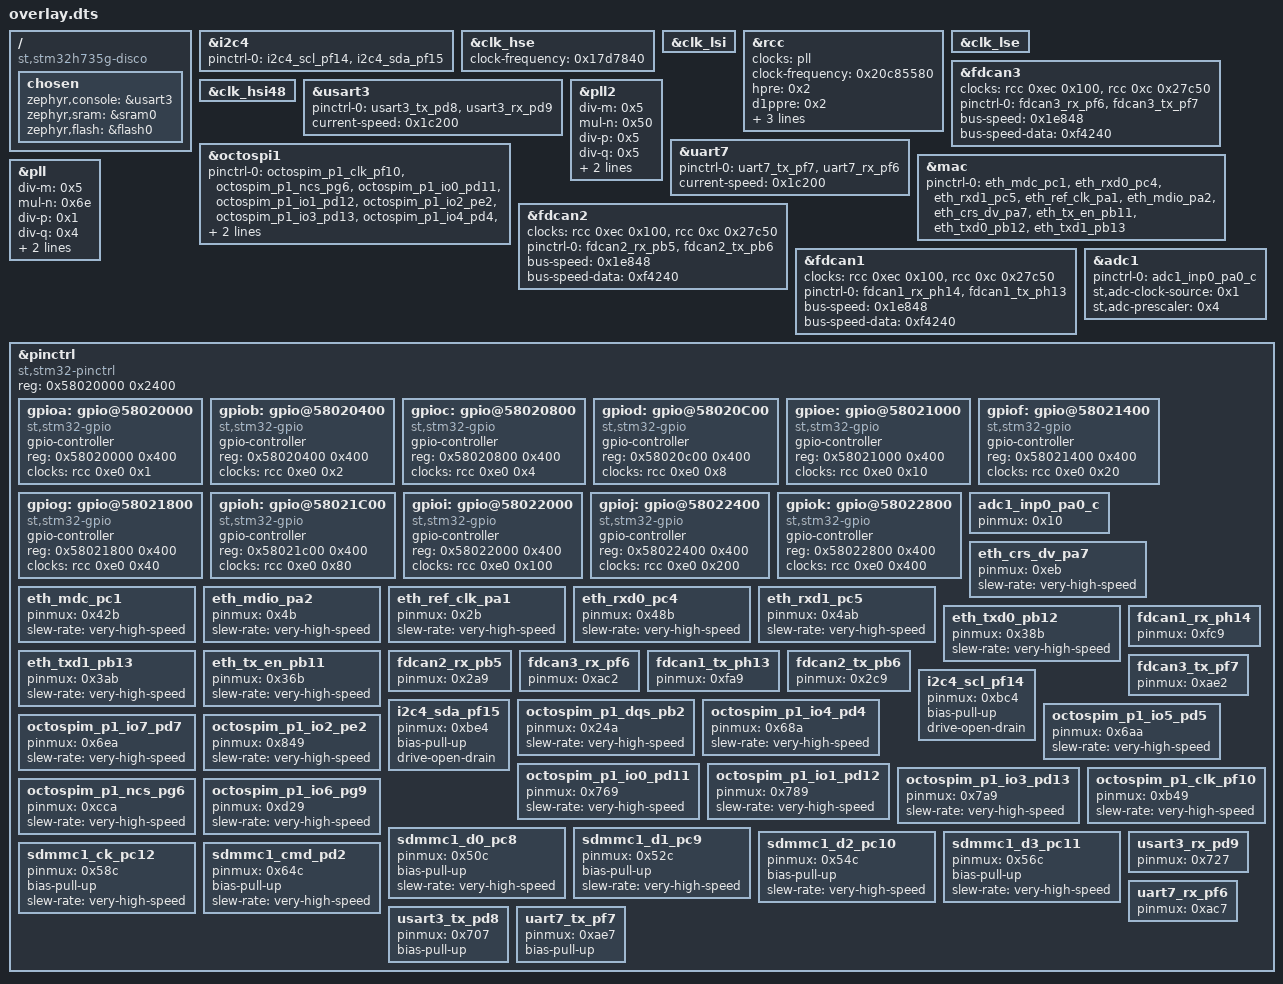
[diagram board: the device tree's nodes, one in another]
/ {
	compatible = "st,stm32h735g-disco";
	chosen {
		zephyr,console = &usart3;
		zephyr,sram = &sram0;
		zephyr,flash = &flash0;
	};
};
&i2c4{
	pinctrl-0 = < &i2c4_scl_pf14 &i2c4_sda_pf15 >;
	pinctrl-names = "default";
};
&clk_hse{
	status = "okay";
	clock-frequency = < 0x17d7840 >;
};
&clk_lsi{
	status = "okay";
};
&rcc{
	clocks = < &pll >;
	clock-frequency = < 0x20c85580 >;
	hpre = < 0x2 >;
	d1ppre = < 0x2 >;
	d2ppre1 = < 0x2 >;
	d2ppre2 = < 0x2 >;
	d3ppre = < 0x2 >;
};
&clk_lse{
	status = "okay";
};
&fdcan3{
	clocks = < &rcc 0xec 0x100 >, < &rcc 0xc 0x27c50 >;
	pinctrl-0 = < &fdcan3_rx_pf6 &fdcan3_tx_pf7 >;
	pinctrl-names = "default";
	bus-speed = < 0x1e848 >;
	bus-speed-data = < 0xf4240 >;
};
&clk_hsi48{
	status = "okay";
};
&usart3{
	status = "okay";
	pinctrl-0 = < &usart3_tx_pd8 &usart3_rx_pd9 >;
	pinctrl-names = "default";
	current-speed = < 0x1c200 >;
};
&pll2{
	status = "okay";
	div-m = < 0x5 >;
	mul-n = < 0x50 >;
	div-p = < 0x5 >;
	div-q = < 0x5 >;
	div-r = < 0x5 >;
	clocks = < &clk_hse >;
};
&octospi1{
	status = "okay";
	pinctrl-0 = < &octospim_p1_clk_pf10 &octospim_p1_ncs_pg6 &octospim_p1_io0_pd11 &octospim_p1_io1_pd12 &octospim_p1_io2_pe2 &octospim_p1_io3_pd13 &octospim_p1_io4_pd4 &octospim_p1_io5_pd5 &octospim_p1_io6_pg9 &octospim_p1_io7_pd7 &octospim_p1_dqs_pb2 >;
	pinctrl-names = "default";
};
&uart7{
	pinctrl-0 = < &uart7_tx_pf7 &uart7_rx_pf6 >;
	pinctrl-names = "default";
	current-speed = < 0x1c200 >;
};
&mac{
	status = "okay";
	pinctrl-0 = < &eth_mdc_pc1 &eth_rxd0_pc4 &eth_rxd1_pc5 &eth_ref_clk_pa1 &eth_mdio_pa2 &eth_crs_dv_pa7 &eth_tx_en_pb11 &eth_txd0_pb12 &eth_txd1_pb13 >;
	pinctrl-names = "default";
};
&fdcan2{
	clocks = < &rcc 0xec 0x100 >, < &rcc 0xc 0x27c50 >;
	status = "okay";
	pinctrl-0 = < &fdcan2_rx_pb5 &fdcan2_tx_pb6 >;
	pinctrl-names = "default";
	bus-speed = < 0x1e848 >;
	bus-speed-data = < 0xf4240 >;
};
&fdcan1{
	clocks = < &rcc 0xec 0x100 >, < &rcc 0xc 0x27c50 >;
	status = "okay";
	pinctrl-0 = < &fdcan1_rx_ph14 &fdcan1_tx_ph13 >;
	pinctrl-names = "default";
	bus-speed = < 0x1e848 >;
	bus-speed-data = < 0xf4240 >;
};
&pll{
	status = "okay";
	div-m = < 0x5 >;
	mul-n = < 0x6e >;
	div-p = < 0x1 >;
	div-q = < 0x4 >;
	div-r = < 0x2 >;
	clocks = < &clk_hse >;
};
&adc1{
	status = "okay";
	pinctrl-0 = < &adc1_inp0_pa0_c >;
	pinctrl-names = "default";
	st,adc-clock-source = < 0x1 >;
	st,adc-prescaler = < 0x4 >;
};
&pinctrl{
	compatible = "st,stm32-pinctrl";
	#address-cells = < 0x1 >;
	#size-cells = < 0x1 >;
	reg = < 0x58020000 0x2400 >;
	gpioa: gpio@58020000 {
		compatible = "st,stm32-gpio";
		gpio-controller;
		#gpio-cells = < 0x2 >;
		reg = < 0x58020000 0x400 >;
		clocks = < &rcc 0xe0 0x1 >;
	};
	gpiob: gpio@58020400 {
		compatible = "st,stm32-gpio";
		gpio-controller;
		#gpio-cells = < 0x2 >;
		reg = < 0x58020400 0x400 >;
		clocks = < &rcc 0xe0 0x2 >;
	};
	gpioc: gpio@58020800 {
		compatible = "st,stm32-gpio";
		gpio-controller;
		#gpio-cells = < 0x2 >;
		reg = < 0x58020800 0x400 >;
		clocks = < &rcc 0xe0 0x4 >;
	};
	gpiod: gpio@58020C00 {
		compatible = "st,stm32-gpio";
		gpio-controller;
		#gpio-cells = < 0x2 >;
		reg = < 0x58020c00 0x400 >;
		clocks = < &rcc 0xe0 0x8 >;
	};
	gpioe: gpio@58021000 {
		compatible = "st,stm32-gpio";
		gpio-controller;
		#gpio-cells = < 0x2 >;
		reg = < 0x58021000 0x400 >;
		clocks = < &rcc 0xe0 0x10 >;
	};
	gpiof: gpio@58021400 {
		compatible = "st,stm32-gpio";
		gpio-controller;
		#gpio-cells = < 0x2 >;
		reg = < 0x58021400 0x400 >;
		clocks = < &rcc 0xe0 0x20 >;
	};
	gpiog: gpio@58021800 {
		compatible = "st,stm32-gpio";
		gpio-controller;
		#gpio-cells = < 0x2 >;
		reg = < 0x58021800 0x400 >;
		clocks = < &rcc 0xe0 0x40 >;
	};
	gpioh: gpio@58021C00 {
		compatible = "st,stm32-gpio";
		gpio-controller;
		#gpio-cells = < 0x2 >;
		reg = < 0x58021c00 0x400 >;
		clocks = < &rcc 0xe0 0x80 >;
	};
	gpioi: gpio@58022000 {
		compatible = "st,stm32-gpio";
		gpio-controller;
		#gpio-cells = < 0x2 >;
		reg = < 0x58022000 0x400 >;
		clocks = < &rcc 0xe0 0x100 >;
	};
	gpioj: gpio@58022400 {
		compatible = "st,stm32-gpio";
		gpio-controller;
		#gpio-cells = < 0x2 >;
		reg = < 0x58022400 0x400 >;
		clocks = < &rcc 0xe0 0x200 >;
	};
	gpiok: gpio@58022800 {
		compatible = "st,stm32-gpio";
		gpio-controller;
		#gpio-cells = < 0x2 >;
		reg = < 0x58022800 0x400 >;
		clocks = < &rcc 0xe0 0x400 >;
	};
	adc1_inp0_pa0_c: adc1_inp0_pa0_c {
		pinmux = < 0x10 >;
	};
	eth_crs_dv_pa7: eth_crs_dv_pa7 {
		pinmux = < 0xeb >;
		slew-rate = "very-high-speed";
	};
	eth_mdc_pc1: eth_mdc_pc1 {
		pinmux = < 0x42b >;
		slew-rate = "very-high-speed";
	};
	eth_mdio_pa2: eth_mdio_pa2 {
		pinmux = < 0x4b >;
		slew-rate = "very-high-speed";
	};
	eth_ref_clk_pa1: eth_ref_clk_pa1 {
		pinmux = < 0x2b >;
		slew-rate = "very-high-speed";
	};
	eth_rxd0_pc4: eth_rxd0_pc4 {
		pinmux = < 0x48b >;
		slew-rate = "very-high-speed";
	};
	eth_rxd1_pc5: eth_rxd1_pc5 {
		pinmux = < 0x4ab >;
		slew-rate = "very-high-speed";
	};
	eth_txd0_pb12: eth_txd0_pb12 {
		pinmux = < 0x38b >;
		slew-rate = "very-high-speed";
	};
	eth_txd1_pb13: eth_txd1_pb13 {
		pinmux = < 0x3ab >;
		slew-rate = "very-high-speed";
	};
	eth_tx_en_pb11: eth_tx_en_pb11 {
		pinmux = < 0x36b >;
		slew-rate = "very-high-speed";
	};
	fdcan1_rx_ph14: fdcan1_rx_ph14 {
		pinmux = < 0xfc9 >;
	};
	fdcan2_rx_pb5: fdcan2_rx_pb5 {
		pinmux = < 0x2a9 >;
	};
	fdcan3_rx_pf6: fdcan3_rx_pf6 {
		pinmux = < 0xac2 >;
	};
	fdcan1_tx_ph13: fdcan1_tx_ph13 {
		pinmux = < 0xfa9 >;
	};
	fdcan2_tx_pb6: fdcan2_tx_pb6 {
		pinmux = < 0x2c9 >;
	};
	fdcan3_tx_pf7: fdcan3_tx_pf7 {
		pinmux = < 0xae2 >;
	};
	i2c4_scl_pf14: i2c4_scl_pf14 {
		pinmux = < 0xbc4 >;
		bias-pull-up;
		drive-open-drain;
	};
	i2c4_sda_pf15: i2c4_sda_pf15 {
		pinmux = < 0xbe4 >;
		bias-pull-up;
		drive-open-drain;
	};
	octospim_p1_dqs_pb2: octospim_p1_dqs_pb2 {
		pinmux = < 0x24a >;
		slew-rate = "very-high-speed";
	};
	octospim_p1_io4_pd4: octospim_p1_io4_pd4 {
		pinmux = < 0x68a >;
		slew-rate = "very-high-speed";
	};
	octospim_p1_io5_pd5: octospim_p1_io5_pd5 {
		pinmux = < 0x6aa >;
		slew-rate = "very-high-speed";
	};
	octospim_p1_io7_pd7: octospim_p1_io7_pd7 {
		pinmux = < 0x6ea >;
		slew-rate = "very-high-speed";
	};
	octospim_p1_io0_pd11: octospim_p1_io0_pd11 {
		pinmux = < 0x769 >;
		slew-rate = "very-high-speed";
	};
	octospim_p1_io1_pd12: octospim_p1_io1_pd12 {
		pinmux = < 0x789 >;
		slew-rate = "very-high-speed";
	};
	octospim_p1_io3_pd13: octospim_p1_io3_pd13 {
		pinmux = < 0x7a9 >;
		slew-rate = "very-high-speed";
	};
	octospim_p1_io2_pe2: octospim_p1_io2_pe2 {
		pinmux = < 0x849 >;
		slew-rate = "very-high-speed";
	};
	octospim_p1_clk_pf10: octospim_p1_clk_pf10 {
		pinmux = < 0xb49 >;
		slew-rate = "very-high-speed";
	};
	octospim_p1_ncs_pg6: octospim_p1_ncs_pg6 {
		pinmux = < 0xcca >;
		slew-rate = "very-high-speed";
	};
	octospim_p1_io6_pg9: octospim_p1_io6_pg9 {
		pinmux = < 0xd29 >;
		slew-rate = "very-high-speed";
	};
	sdmmc1_d0_pc8: sdmmc1_d0_pc8 {
		pinmux = < 0x50c >;
		bias-pull-up;
		slew-rate = "very-high-speed";
	};
	sdmmc1_d1_pc9: sdmmc1_d1_pc9 {
		pinmux = < 0x52c >;
		bias-pull-up;
		slew-rate = "very-high-speed";
	};
	sdmmc1_d2_pc10: sdmmc1_d2_pc10 {
		pinmux = < 0x54c >;
		bias-pull-up;
		slew-rate = "very-high-speed";
	};
	sdmmc1_d3_pc11: sdmmc1_d3_pc11 {
		pinmux = < 0x56c >;
		bias-pull-up;
		slew-rate = "very-high-speed";
	};
	sdmmc1_ck_pc12: sdmmc1_ck_pc12 {
		pinmux = < 0x58c >;
		bias-pull-up;
		slew-rate = "very-high-speed";
	};
	sdmmc1_cmd_pd2: sdmmc1_cmd_pd2 {
		pinmux = < 0x64c >;
		bias-pull-up;
		slew-rate = "very-high-speed";
	};
	usart3_rx_pd9: usart3_rx_pd9 {
		pinmux = < 0x727 >;
	};
	uart7_rx_pf6: uart7_rx_pf6 {
		pinmux = < 0xac7 >;
	};
	usart3_tx_pd8: usart3_tx_pd8 {
		pinmux = < 0x707 >;
		bias-pull-up;
	};
	uart7_tx_pf7: uart7_tx_pf7 {
		pinmux = < 0xae7 >;
		bias-pull-up;
	};
};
